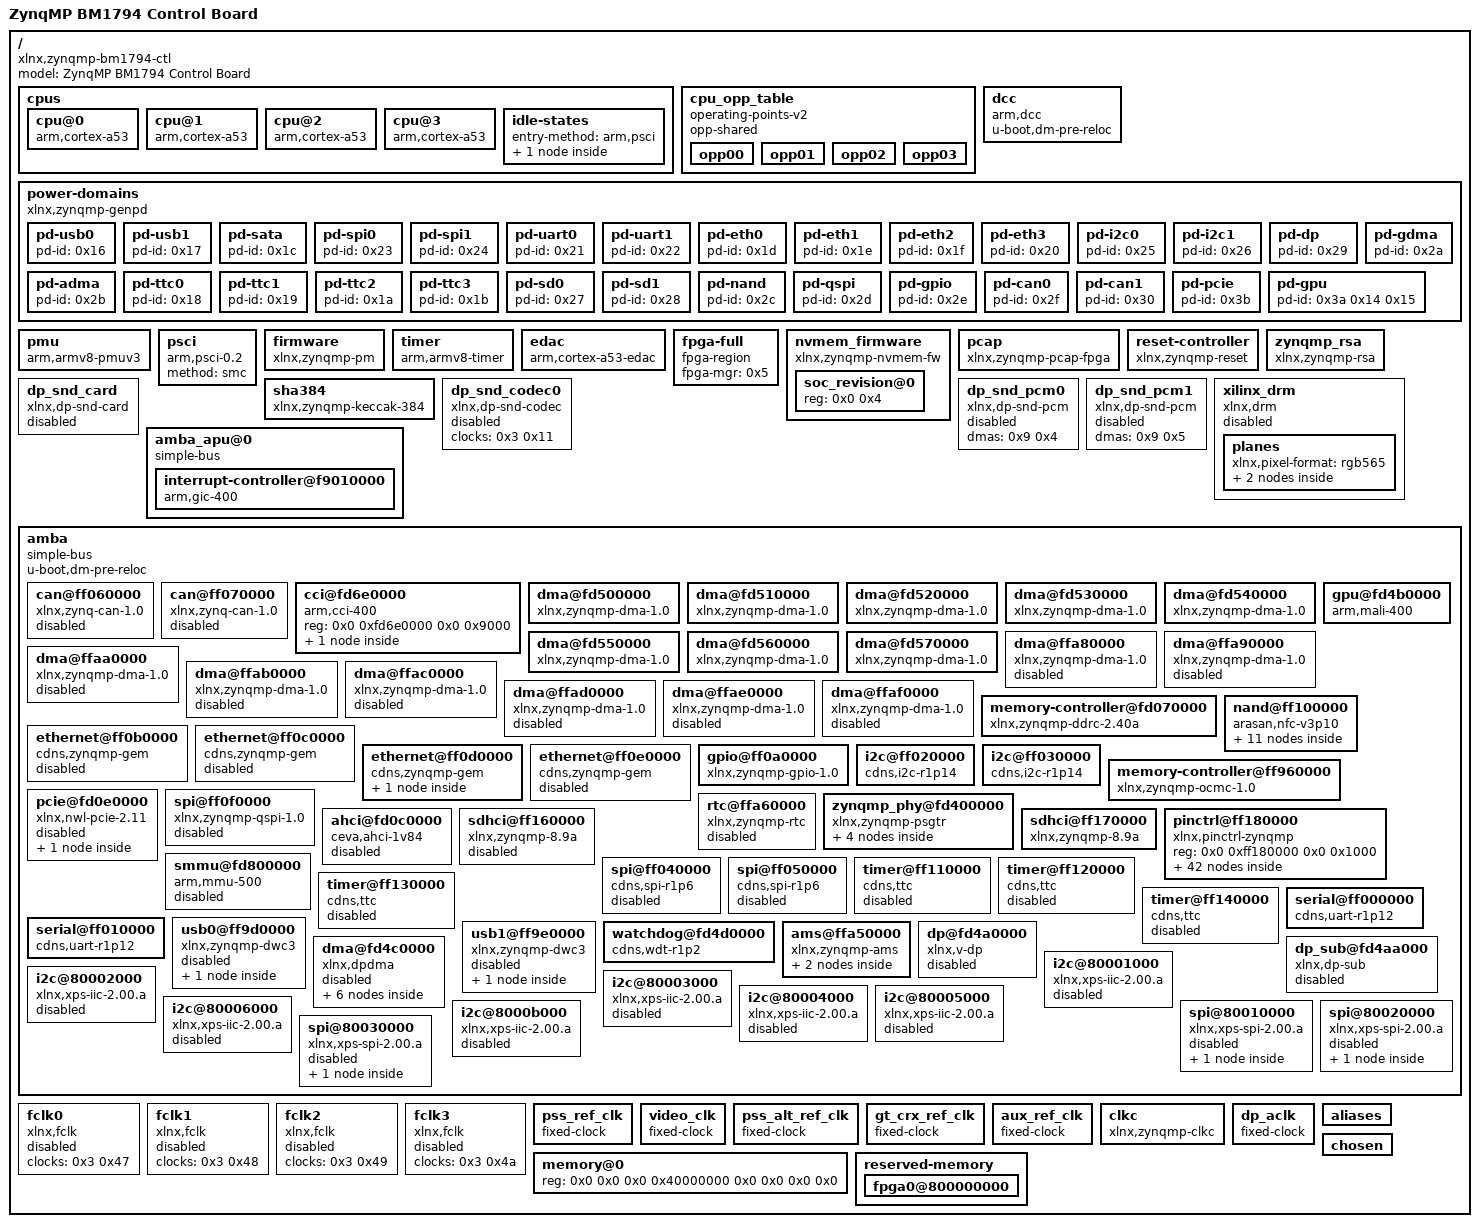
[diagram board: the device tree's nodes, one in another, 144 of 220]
/dts-v1/;

/memreserve/	0x000000003d1ba000 0x0000000000009000;
/memreserve/	0x000000003d1c6000 0x0000000000cfb1b4;
/ {
	compatible = "xlnx,zynqmp-bm1794-ctl", "xlnx,zynqmp";
	#address-cells = <0x2>;
	#size-cells = <0x2>;
	model = "ZynqMP BM1794 Control Board";

	cpus {
		#address-cells = <0x1>;
		#size-cells = <0x0>;

		cpu@0 {
			compatible = "arm,cortex-a53", "arm,armv8";
			device_type = "cpu";
			enable-method = "psci";
			operating-points-v2 = <0x1>;
			reg = <0x0>;
			cpu-idle-states = <0x2>;
			clocks = <0x3 0xa>;
		};

		cpu@1 {
			compatible = "arm,cortex-a53", "arm,armv8";
			device_type = "cpu";
			enable-method = "psci";
			reg = <0x1>;
			operating-points-v2 = <0x1>;
			cpu-idle-states = <0x2>;
		};

		cpu@2 {
			compatible = "arm,cortex-a53", "arm,armv8";
			device_type = "cpu";
			enable-method = "psci";
			reg = <0x2>;
			operating-points-v2 = <0x1>;
			cpu-idle-states = <0x2>;
		};

		cpu@3 {
			compatible = "arm,cortex-a53", "arm,armv8";
			device_type = "cpu";
			enable-method = "psci";
			reg = <0x3>;
			operating-points-v2 = <0x1>;
			cpu-idle-states = <0x2>;
		};

		idle-states {
			entry-method = "arm,psci";

			cpu-sleep-0 {
				compatible = "arm,idle-state";
				arm,psci-suspend-param = <0x40000000>;
				local-timer-stop;
				entry-latency-us = <0x12c>;
				exit-latency-us = <0x258>;
				min-residency-us = <0x2710>;
				linux,phandle = <0x2>;
				phandle = <0x2>;
			};
		};
	};

	cpu_opp_table {
		compatible = "operating-points-v2";
		opp-shared;
		linux,phandle = <0x1>;
		phandle = <0x1>;

		opp00 {
			opp-hz = <0x0 0x47868bf4>;
			opp-microvolt = <0xf4240>;
			clock-latency-ns = <0x7a120>;
		};

		opp01 {
			opp-hz = <0x0 0x23c345fa>;
			opp-microvolt = <0xf4240>;
			clock-latency-ns = <0x7a120>;
		};

		opp02 {
			opp-hz = <0x0 0x17d783fc>;
			opp-microvolt = <0xf4240>;
			clock-latency-ns = <0x7a120>;
		};

		opp03 {
			opp-hz = <0x0 0x11e1a2fd>;
			opp-microvolt = <0xf4240>;
			clock-latency-ns = <0x7a120>;
		};
	};

	dcc {
		compatible = "arm,dcc";
		status = "okay";
		u-boot,dm-pre-reloc;
	};

	power-domains {
		compatible = "xlnx,zynqmp-genpd";

		pd-usb0 {
			#power-domain-cells = <0x0>;
			pd-id = <0x16>;
			linux,phandle = <0x38>;
			phandle = <0x38>;
		};

		pd-usb1 {
			#power-domain-cells = <0x0>;
			pd-id = <0x17>;
			linux,phandle = <0x39>;
			phandle = <0x39>;
		};

		pd-sata {
			#power-domain-cells = <0x0>;
			pd-id = <0x1c>;
			linux,phandle = <0x28>;
			phandle = <0x28>;
		};

		pd-spi0 {
			#power-domain-cells = <0x0>;
			pd-id = <0x23>;
			linux,phandle = <0x2e>;
			phandle = <0x2e>;
		};

		pd-spi1 {
			#power-domain-cells = <0x0>;
			pd-id = <0x24>;
			linux,phandle = <0x2f>;
			phandle = <0x2f>;
		};

		pd-uart0 {
			#power-domain-cells = <0x0>;
			pd-id = <0x21>;
			linux,phandle = <0x34>;
			phandle = <0x34>;
		};

		pd-uart1 {
			#power-domain-cells = <0x0>;
			pd-id = <0x22>;
			linux,phandle = <0x36>;
			phandle = <0x36>;
		};

		pd-eth0 {
			#power-domain-cells = <0x0>;
			pd-id = <0x1d>;
			linux,phandle = <0x13>;
			phandle = <0x13>;
		};

		pd-eth1 {
			#power-domain-cells = <0x0>;
			pd-id = <0x1e>;
			linux,phandle = <0x14>;
			phandle = <0x14>;
		};

		pd-eth2 {
			#power-domain-cells = <0x0>;
			pd-id = <0x1f>;
			linux,phandle = <0x15>;
			phandle = <0x15>;
		};

		pd-eth3 {
			#power-domain-cells = <0x0>;
			pd-id = <0x20>;
			linux,phandle = <0x18>;
			phandle = <0x18>;
		};

		pd-i2c0 {
			#power-domain-cells = <0x0>;
			pd-id = <0x25>;
			linux,phandle = <0x1b>;
			phandle = <0x1b>;
		};

		pd-i2c1 {
			#power-domain-cells = <0x0>;
			pd-id = <0x26>;
			linux,phandle = <0x1f>;
			phandle = <0x1f>;
		};

		pd-dp {
			#power-domain-cells = <0x0>;
			pd-id = <0x29>;
			linux,phandle = <0x3a>;
			phandle = <0x3a>;
		};

		pd-gdma {
			#power-domain-cells = <0x0>;
			pd-id = <0x2a>;
			linux,phandle = <0xf>;
			phandle = <0xf>;
		};

		pd-adma {
			#power-domain-cells = <0x0>;
			pd-id = <0x2b>;
			linux,phandle = <0x11>;
			phandle = <0x11>;
		};

		pd-ttc0 {
			#power-domain-cells = <0x0>;
			pd-id = <0x18>;
			linux,phandle = <0x30>;
			phandle = <0x30>;
		};

		pd-ttc1 {
			#power-domain-cells = <0x0>;
			pd-id = <0x19>;
			linux,phandle = <0x31>;
			phandle = <0x31>;
		};

		pd-ttc2 {
			#power-domain-cells = <0x0>;
			pd-id = <0x1a>;
			linux,phandle = <0x32>;
			phandle = <0x32>;
		};

		pd-ttc3 {
			#power-domain-cells = <0x0>;
			pd-id = <0x1b>;
			linux,phandle = <0x33>;
			phandle = <0x33>;
		};

		pd-sd0 {
			#power-domain-cells = <0x0>;
			pd-id = <0x27>;
			linux,phandle = <0x2a>;
			phandle = <0x2a>;
		};

		pd-sd1 {
			#power-domain-cells = <0x0>;
			pd-id = <0x28>;
			linux,phandle = <0x2c>;
			phandle = <0x2c>;
		};

		pd-nand {
			#power-domain-cells = <0x0>;
			pd-id = <0x2c>;
			linux,phandle = <0x12>;
			phandle = <0x12>;
		};

		pd-qspi {
			#power-domain-cells = <0x0>;
			pd-id = <0x2d>;
			linux,phandle = <0x25>;
			phandle = <0x25>;
		};

		pd-gpio {
			#power-domain-cells = <0x0>;
			pd-id = <0x2e>;
			linux,phandle = <0x19>;
			phandle = <0x19>;
		};

		pd-can0 {
			#power-domain-cells = <0x0>;
			pd-id = <0x2f>;
			linux,phandle = <0xc>;
			phandle = <0xc>;
		};

		pd-can1 {
			#power-domain-cells = <0x0>;
			pd-id = <0x30>;
			linux,phandle = <0xd>;
			phandle = <0xd>;
		};

		pd-pcie {
			#power-domain-cells = <0x0>;
			pd-id = <0x3b>;
			linux,phandle = <0x24>;
			phandle = <0x24>;
		};

		pd-gpu {
			#power-domain-cells = <0x0>;
			pd-id = <0x3a 0x14 0x15>;
			linux,phandle = <0x10>;
			phandle = <0x10>;
		};
	};

	pmu {
		compatible = "arm,armv8-pmuv3";
		interrupt-parent = <0x4>;
		interrupts = <0x0 0x8f 0x4 0x0 0x90 0x4 0x0 0x91 0x4 0x0 0x92 0x4>;
	};

	psci {
		compatible = "arm,psci-0.2";
		method = "smc";
	};

	firmware {
		compatible = "xlnx,zynqmp-pm";
		method = "smc";
		interrupt-parent = <0x4>;
		interrupts = <0x0 0x23 0x4>;
	};

	timer {
		compatible = "arm,armv8-timer";
		interrupt-parent = <0x4>;
		interrupts = <0x1 0xd 0xf08 0x1 0xe 0xf08 0x1 0xb 0xf08 0x1 0xa 0xf08>;
	};

	edac {
		compatible = "arm,cortex-a53-edac";
	};

	fpga-full {
		compatible = "fpga-region";
		fpga-mgr = <0x5>;
		#address-cells = <0x2>;
		#size-cells = <0x2>;
	};

	nvmem_firmware {
		compatible = "xlnx,zynqmp-nvmem-fw";
		#address-cells = <0x1>;
		#size-cells = <0x1>;

		soc_revision@0 {
			reg = <0x0 0x4>;
			linux,phandle = <0x26>;
			phandle = <0x26>;
		};
	};

	pcap {
		compatible = "xlnx,zynqmp-pcap-fpga";
		linux,phandle = <0x5>;
		phandle = <0x5>;
	};

	reset-controller {
		compatible = "xlnx,zynqmp-reset";
		#reset-cells = <0x1>;
		linux,phandle = <0x27>;
		phandle = <0x27>;
	};

	zynqmp_rsa {
		compatible = "xlnx,zynqmp-rsa";
	};

	sha384 {
		compatible = "xlnx,zynqmp-keccak-384";
	};

	dp_snd_card {
		compatible = "xlnx,dp-snd-card";
		status = "disabled";
		xlnx,dp-snd-pcm = <0x6 0x7>;
		xlnx,dp-snd-codec = <0x8>;
	};

	dp_snd_codec0 {
		compatible = "xlnx,dp-snd-codec";
		status = "disabled";
		clock-names = "aud_clk";
		clocks = <0x3 0x11>;
		linux,phandle = <0x8>;
		phandle = <0x8>;
	};

	dp_snd_pcm0 {
		compatible = "xlnx,dp-snd-pcm";
		status = "disabled";
		dmas = <0x9 0x4>;
		dma-names = "tx";
		linux,phandle = <0x6>;
		phandle = <0x6>;
	};

	dp_snd_pcm1 {
		compatible = "xlnx,dp-snd-pcm";
		status = "disabled";
		dmas = <0x9 0x5>;
		dma-names = "tx";
		linux,phandle = <0x7>;
		phandle = <0x7>;
	};

	xilinx_drm {
		compatible = "xlnx,drm";
		status = "disabled";
		xlnx,encoder-slave = <0xa>;
		xlnx,connector-type = "DisplayPort";
		xlnx,dp-sub = <0xb>;
		clocks = <0x3 0x10>;

		planes {
			xlnx,pixel-format = "rgb565";

			plane0 {
				dmas = <0x9 0x3>;
				dma-names = "dma0";
			};

			plane1 {
				dmas = <0x9 0x0 0x9 0x1 0x9 0x2>;
				dma-names = "dma0", "dma1", "dma2";
			};
		};
	};

	amba_apu@0 {
		compatible = "simple-bus";
		#address-cells = <0x2>;
		#size-cells = <0x1>;
		ranges = <0x0 0x0 0x0 0x0 0xffffffff>;

		interrupt-controller@f9010000 {
			compatible = "arm,gic-400", "arm,cortex-a15-gic";
			#interrupt-cells = <0x3>;
			reg = <0x0 0xf9010000 0x10000 0x0 0xf9020000 0x20000 0x0 0xf9040000 0x20000 0x0 0xf9060000 0x20000>;
			interrupt-controller;
			interrupt-parent = <0x4>;
			interrupts = <0x1 0x9 0xf04>;
			linux,phandle = <0x4>;
			phandle = <0x4>;
		};
	};

	amba {
		compatible = "simple-bus";
		u-boot,dm-pre-reloc;
		#address-cells = <0x2>;
		#size-cells = <0x2>;
		ranges;

		can@ff060000 {
			compatible = "xlnx,zynq-can-1.0";
			status = "disabled";
			clock-names = "can_clk", "pclk";
			reg = <0x0 0xff060000 0x0 0x1000>;
			interrupts = <0x0 0x17 0x4>;
			interrupt-parent = <0x4>;
			tx-fifo-depth = <0x40>;
			rx-fifo-depth = <0x40>;
			power-domains = <0xc>;
			clocks = <0x3 0x3f 0x3 0x1f>;
		};

		can@ff070000 {
			compatible = "xlnx,zynq-can-1.0";
			status = "disabled";
			clock-names = "can_clk", "pclk";
			reg = <0x0 0xff070000 0x0 0x1000>;
			interrupts = <0x0 0x18 0x4>;
			interrupt-parent = <0x4>;
			tx-fifo-depth = <0x40>;
			rx-fifo-depth = <0x40>;
			power-domains = <0xd>;
			clocks = <0x3 0x40 0x3 0x1f>;
		};

		cci@fd6e0000 {
			compatible = "arm,cci-400";
			reg = <0x0 0xfd6e0000 0x0 0x9000>;
			ranges = <0x0 0x0 0xfd6e0000 0x10000>;
			#address-cells = <0x1>;
			#size-cells = <0x1>;

			pmu@9000 {
				compatible = "arm,cci-400-pmu,r1";
				reg = <0x9000 0x5000>;
				interrupt-parent = <0x4>;
				interrupts = <0x0 0x7b 0x4 0x0 0x7b 0x4 0x0 0x7b 0x4 0x0 0x7b 0x4 0x0 0x7b 0x4>;
			};
		};

		dma@fd500000 {
			status = "okay";
			compatible = "xlnx,zynqmp-dma-1.0";
			reg = <0x0 0xfd500000 0x0 0x1000>;
			interrupt-parent = <0x4>;
			interrupts = <0x0 0x7c 0x4>;
			clock-names = "clk_main", "clk_apb";
			xlnx,bus-width = <0x80>;
			#stream-id-cells = <0x1>;
			iommus = <0xe 0x14e8>;
			power-domains = <0xf>;
			clocks = <0x3 0x13 0x3 0x1f>;
		};

		dma@fd510000 {
			status = "okay";
			compatible = "xlnx,zynqmp-dma-1.0";
			reg = <0x0 0xfd510000 0x0 0x1000>;
			interrupt-parent = <0x4>;
			interrupts = <0x0 0x7d 0x4>;
			clock-names = "clk_main", "clk_apb";
			xlnx,bus-width = <0x80>;
			#stream-id-cells = <0x1>;
			iommus = <0xe 0x14e9>;
			power-domains = <0xf>;
			clocks = <0x3 0x13 0x3 0x1f>;
		};

		dma@fd520000 {
			status = "okay";
			compatible = "xlnx,zynqmp-dma-1.0";
			reg = <0x0 0xfd520000 0x0 0x1000>;
			interrupt-parent = <0x4>;
			interrupts = <0x0 0x7e 0x4>;
			clock-names = "clk_main", "clk_apb";
			xlnx,bus-width = <0x80>;
			#stream-id-cells = <0x1>;
			iommus = <0xe 0x14ea>;
			power-domains = <0xf>;
			clocks = <0x3 0x13 0x3 0x1f>;
		};

		dma@fd530000 {
			status = "okay";
			compatible = "xlnx,zynqmp-dma-1.0";
			reg = <0x0 0xfd530000 0x0 0x1000>;
			interrupt-parent = <0x4>;
			interrupts = <0x0 0x7f 0x4>;
			clock-names = "clk_main", "clk_apb";
			xlnx,bus-width = <0x80>;
			#stream-id-cells = <0x1>;
			iommus = <0xe 0x14eb>;
			power-domains = <0xf>;
			clocks = <0x3 0x13 0x3 0x1f>;
		};

		dma@fd540000 {
			status = "okay";
			compatible = "xlnx,zynqmp-dma-1.0";
			reg = <0x0 0xfd540000 0x0 0x1000>;
			interrupt-parent = <0x4>;
			interrupts = <0x0 0x80 0x4>;
			clock-names = "clk_main", "clk_apb";
			xlnx,bus-width = <0x80>;
			#stream-id-cells = <0x1>;
			iommus = <0xe 0x14ec>;
			power-domains = <0xf>;
			clocks = <0x3 0x13 0x3 0x1f>;
		};

		dma@fd550000 {
			status = "okay";
			compatible = "xlnx,zynqmp-dma-1.0";
			reg = <0x0 0xfd550000 0x0 0x1000>;
			interrupt-parent = <0x4>;
			interrupts = <0x0 0x81 0x4>;
			clock-names = "clk_main", "clk_apb";
			xlnx,bus-width = <0x80>;
			#stream-id-cells = <0x1>;
			iommus = <0xe 0x14ed>;
			power-domains = <0xf>;
			clocks = <0x3 0x13 0x3 0x1f>;
		};

		dma@fd560000 {
			status = "okay";
			compatible = "xlnx,zynqmp-dma-1.0";
			reg = <0x0 0xfd560000 0x0 0x1000>;
			interrupt-parent = <0x4>;
			interrupts = <0x0 0x82 0x4>;
			clock-names = "clk_main", "clk_apb";
			xlnx,bus-width = <0x80>;
			#stream-id-cells = <0x1>;
			iommus = <0xe 0x14ee>;
			power-domains = <0xf>;
			clocks = <0x3 0x13 0x3 0x1f>;
		};

		dma@fd570000 {
			status = "okay";
			compatible = "xlnx,zynqmp-dma-1.0";
			reg = <0x0 0xfd570000 0x0 0x1000>;
			interrupt-parent = <0x4>;
			interrupts = <0x0 0x83 0x4>;
			clock-names = "clk_main", "clk_apb";
			xlnx,bus-width = <0x80>;
			#stream-id-cells = <0x1>;
			iommus = <0xe 0x14ef>;
			power-domains = <0xf>;
			clocks = <0x3 0x13 0x3 0x1f>;
		};

		gpu@fd4b0000 {
			status = "okay";
			compatible = "arm,mali-400", "arm,mali-utgard";
			reg = <0x0 0xfd4b0000 0x0 0x10000>;
			interrupt-parent = <0x4>;
			interrupts = <0x0 0x84 0x4 0x0 0x84 0x4 0x0 0x84 0x4 0x0 0x84 0x4 0x0 0x84 0x4 0x0 0x84 0x4>;
			interrupt-names = "IRQGP", "IRQGPMMU", "IRQPP0", "IRQPPMMU0", "IRQPP1", "IRQPPMMU1";
			clock-names = "gpu", "gpu_pp0", "gpu_pp1";
			power-domains = <0x10>;
			clocks = <0x3 0x18 0x3 0x19 0x3 0x1a>;
		};

		dma@ffa80000 {
			status = "disabled";
			compatible = "xlnx,zynqmp-dma-1.0";
			clock-names = "clk_main", "clk_apb";
			reg = <0x0 0xffa80000 0x0 0x1000>;
			interrupt-parent = <0x4>;
			interrupts = <0x0 0x4d 0x4>;
			xlnx,bus-width = <0x40>;
			#stream-id-cells = <0x1>;
			power-domains = <0x11>;
			clocks = <0x3 0x44 0x3 0x1f>;
		};

		dma@ffa90000 {
			status = "disabled";
			compatible = "xlnx,zynqmp-dma-1.0";
			clock-names = "clk_main", "clk_apb";
			reg = <0x0 0xffa90000 0x0 0x1000>;
			interrupt-parent = <0x4>;
			interrupts = <0x0 0x4e 0x4>;
			xlnx,bus-width = <0x40>;
			#stream-id-cells = <0x1>;
			power-domains = <0x11>;
			clocks = <0x3 0x44 0x3 0x1f>;
		};

		dma@ffaa0000 {
			status = "disabled";
			compatible = "xlnx,zynqmp-dma-1.0";
			clock-names = "clk_main", "clk_apb";
			reg = <0x0 0xffaa0000 0x0 0x1000>;
			interrupt-parent = <0x4>;
			interrupts = <0x0 0x4f 0x4>;
			xlnx,bus-width = <0x40>;
			#stream-id-cells = <0x1>;
			power-domains = <0x11>;
			clocks = <0x3 0x44 0x3 0x1f>;
		};

		dma@ffab0000 {
			status = "disabled";
			compatible = "xlnx,zynqmp-dma-1.0";
			clock-names = "clk_main", "clk_apb";
			reg = <0x0 0xffab0000 0x0 0x1000>;
			interrupt-parent = <0x4>;
			interrupts = <0x0 0x50 0x4>;
			xlnx,bus-width = <0x40>;
			#stream-id-cells = <0x1>;
			power-domains = <0x11>;
			clocks = <0x3 0x44 0x3 0x1f>;
		};

		dma@ffac0000 {
			status = "disabled";
			compatible = "xlnx,zynqmp-dma-1.0";
			clock-names = "clk_main", "clk_apb";
			reg = <0x0 0xffac0000 0x0 0x1000>;
			interrupt-parent = <0x4>;
			interrupts = <0x0 0x51 0x4>;
			xlnx,bus-width = <0x40>;
			#stream-id-cells = <0x1>;
			power-domains = <0x11>;
			clocks = <0x3 0x44 0x3 0x1f>;
		};

		dma@ffad0000 {
			status = "disabled";
			compatible = "xlnx,zynqmp-dma-1.0";
			clock-names = "clk_main", "clk_apb";
			reg = <0x0 0xffad0000 0x0 0x1000>;
			interrupt-parent = <0x4>;
			interrupts = <0x0 0x52 0x4>;
			xlnx,bus-width = <0x40>;
			#stream-id-cells = <0x1>;
			power-domains = <0x11>;
			clocks = <0x3 0x44 0x3 0x1f>;
		};

		dma@ffae0000 {
			status = "disabled";
			compatible = "xlnx,zynqmp-dma-1.0";
			clock-names = "clk_main", "clk_apb";
			reg = <0x0 0xffae0000 0x0 0x1000>;
			interrupt-parent = <0x4>;
			interrupts = <0x0 0x53 0x4>;
			xlnx,bus-width = <0x40>;
			#stream-id-cells = <0x1>;
			power-domains = <0x11>;
			clocks = <0x3 0x44 0x3 0x1f>;
		};

		dma@ffaf0000 {
			status = "disabled";
			compatible = "xlnx,zynqmp-dma-1.0";
			clock-names = "clk_main", "clk_apb";
			reg = <0x0 0xffaf0000 0x0 0x1000>;
			interrupt-parent = <0x4>;
			interrupts = <0x0 0x54 0x4>;
			xlnx,bus-width = <0x40>;
			#stream-id-cells = <0x1>;
			power-domains = <0x11>;
			clocks = <0x3 0x44 0x3 0x1f>;
		};

		memory-controller@fd070000 {
			compatible = "xlnx,zynqmp-ddrc-2.40a";
			reg = <0x0 0xfd070000 0x0 0x30000>;
			interrupt-parent = <0x4>;
			interrupts = <0x0 0x70 0x4>;
		};

		nand@ff100000 {
			compatible = "arasan,nfc-v3p10";
			status = "okay";
			reg = <0x0 0xff100000 0x0 0x1000>;
			clock-names = "clk_sys", "clk_flash";
			interrupt-parent = <0x4>;
			interrupts = <0x0 0xe 0x4>;
			#address-cells = <0x1>;
			#size-cells = <0x0>;
			#stream-id-cells = <0x1>;
			iommus = <0xe 0x872>;
			power-domains = <0x12>;
			clocks = <0x3 0x3c 0x3 0x1f>;
			arasan,has-mdma;

			nand@0 {
				reg = <0x0>;
				#address-cells = <0x2>;
				#size-cells = <0x1>;

				partition@0 {
					label = "nand-fsbl-uboot";
					reg = <0x0 0x0 0x800000>;
				};

				partition@1 {
					label = "nand-fsbl-uboot";
					reg = <0x0 0x800000 0x800000>;
				};

				partition@2 {
					label = "nand-fsbl-uboot";
					reg = <0x0 0x1000000 0x800000>;
				};

				partition@3 {
					label = "nand-fsbl-reserve";
					reg = <0x0 0x1800000 0x200000>;
				};

				partition@4 {
					label = "nand-linux-uimage";
					reg = <0x0 0x1a00000 0x1000000>;
				};

				partition@5 {
					label = "device-tree";
					reg = <0x0 0x2a00000 0x100000>;
				};

				partition@6 {
					label = "nand-uramdisk-image";
					reg = <0x0 0x2b00000 0x2000000>;
				};

				partition@7 {
					label = "nand-config";
					reg = <0x0 0x4b00000 0x800000>;
				};

				partition@8 {
					label = "nand-reserve";
					reg = <0x0 0x5300000 0xd00000>;
				};

				partition@9 {
					label = "nand-uramdisk-bak";
					reg = <0x0 0x6000000 0x2000000>;
				};
			};
		};

		ethernet@ff0b0000 {
			compatible = "cdns,zynqmp-gem";
			status = "disabled";
			interrupt-parent = <0x4>;
			interrupts = <0x0 0x39 0x4 0x0 0x39 0x4>;
			reg = <0x0 0xff0b0000 0x0 0x1000>;
			clock-names = "pclk", "tx_clk", "hclk";
			#address-cells = <0x1>;
			#size-cells = <0x0>;
			#stream-id-cells = <0x1>;
			iommus = <0xe 0x874>;
			power-domains = <0x13>;
			clocks = <0x3 0x2d 0x3 0x2d 0x3 0x31>;
		};

		ethernet@ff0c0000 {
			compatible = "cdns,zynqmp-gem";
			status = "disabled";
			interrupt-parent = <0x4>;
			interrupts = <0x0 0x3b 0x4 0x0 0x3b 0x4>;
			reg = <0x0 0xff0c0000 0x0 0x1000>;
			clock-names = "pclk", "tx_clk", "hclk";
			#address-cells = <0x1>;
			#size-cells = <0x0>;
			#stream-id-cells = <0x1>;
			iommus = <0xe 0x875>;
			power-domains = <0x14>;
			clocks = <0x3 0x2e 0x3 0x2e 0x3 0x32>;
		};

		ethernet@ff0d0000 {
			compatible = "cdns,zynqmp-gem";
			status = "okay";
			interrupt-parent = <0x4>;
			interrupts = <0x0 0x3d 0x4 0x0 0x3d 0x4>;
			reg = <0x0 0xff0d0000 0x0 0x1000>;
			clock-names = "pclk", "tx_clk", "hclk";
			#address-cells = <0x1>;
			#size-cells = <0x0>;
			#stream-id-cells = <0x1>;
			iommus = <0xe 0x876>;
			power-domains = <0x15>;
			clocks = <0x3 0x2f 0x3 0x2f 0x3 0x33>;
			phy-handle = <0x16>;
			phy-mode = "rgmii-id";
			pinctrl-names = "default";
			pinctrl-0 = <0x17>;

			phy@0 {
				reg = <0x0>;
				ti,rx-internal-delay = <0x8>;
				ti,tx-internal-delay = <0xa>;
				ti,fifo-depth = <0x1>;
				ti,rxctrl-strap-worka;
				linux,phandle = <0x16>;
				phandle = <0x16>;
			};
		};

		ethernet@ff0e0000 {
			compatible = "cdns,zynqmp-gem";
			status = "disabled";
			interrupt-parent = <0x4>;
			interrupts = <0x0 0x3f 0x4 0x0 0x3f 0x4>;
			reg = <0x0 0xff0e0000 0x0 0x1000>;
			clock-names = "pclk", "hclk", "tx_clk", "rx_clk";
			#address-cells = <0x1>;
			#size-cells = <0x0>;
			#stream-id-cells = <0x1>;
			iommus = <0xe 0x877>;
			power-domains = <0x18>;
			clocks = <0x3 0x1f 0x3 0x34 0x3 0x30 0x3 0x34>;
		};

		gpio@ff0a0000 {
			compatible = "xlnx,zynqmp-gpio-1.0";
			status = "okay";
			#gpio-cells = <0x2>;
			interrupt-parent = <0x4>;
			interrupts = <0x0 0x10 0x4>;
			interrupt-controller;
			#interrupt-cells = <0x2>;
			reg = <0x0 0xff0a0000 0x0 0x1000>;
			gpio-controller;
			power-domains = <0x19>;
			clocks = <0x3 0x1f>;
			pinctrl-names = "default";
			pinctrl-0 = <0x1a>;
			linux,phandle = <0x1e>;
			phandle = <0x1e>;
		};

		i2c@ff020000 {
			compatible = "cdns,i2c-r1p14", "cdns,i2c-r1p10";
			status = "okay";
			interrupt-parent = <0x4>;
			interrupts = <0x0 0x11 0x4>;
			reg = <0x0 0xff020000 0x0 0x1000>;
			#address-cells = <0x1>;
			#size-cells = <0x0>;
			power-domains = <0x1b>;
			clocks = <0x3 0x3d>;
			clock-frequency = <0x61a80>;
			pinctrl-names = "default", "gpio";
			pinctrl-0 = <0x1c>;
			pinctrl-1 = <0x1d>;
			scl-gpios = <0x1e 0x22 0x0>;
			sda-gpios = <0x1e 0x23 0x0>;
		};

		i2c@ff030000 {
			compatible = "cdns,i2c-r1p14", "cdns,i2c-r1p10";
			status = "okay";
			interrupt-parent = <0x4>;
			interrupts = <0x0 0x12 0x4>;
			reg = <0x0 0xff030000 0x0 0x1000>;
			#address-cells = <0x1>;
			#size-cells = <0x0>;
			power-domains = <0x1f>;
			clocks = <0x3 0x3e>;
			clock-frequency = <0x61a80>;
			pinctrl-names = "default", "gpio";
			pinctrl-0 = <0x20>;
			pinctrl-1 = <0x21>;
			scl-gpios = <0x1e 0x24 0x0>;
			sda-gpios = <0x1e 0x25 0x0>;
		};

		memory-controller@ff960000 {
			compatible = "xlnx,zynqmp-ocmc-1.0";
			reg = <0x0 0xff960000 0x0 0x1000>;
			interrupt-parent = <0x4>;
			interrupts = <0x0 0xa 0x4>;
		};

		pcie@fd0e0000 {
			compatible = "xlnx,nwl-pcie-2.11";
			status = "disabled";
			#address-cells = <0x3>;
			#size-cells = <0x2>;
			#interrupt-cells = <0x1>;
			msi-controller;
			device_type = "pci";
			interrupt-parent = <0x4>;
			interrupts = <0x0 0x76 0x4 0x0 0x75 0x4 0x0 0x74 0x4 0x0 0x73 0x4 0x0 0x72 0x4>;
			interrupt-names = "misc", "dummy", "intx", "msi1", "msi0";
			msi-parent = <0x22>;
			reg = <0x0 0xfd0e0000 0x0 0x1000 0x0 0xfd480000 0x0 0x1000 0x80 0x0 0x0 0x1000000>;
			reg-names = "breg", "pcireg", "cfg";
			ranges = <0x2000000 0x0 0xe0000000 0x0 0xe0000000 0x0 0x10000000 0x43000000 0x6 0x0 0x6 0x0 0x2 0x0>;
			bus-range = <0x0 0xff>;
			interrupt-map-mask = <0x0 0x0 0x0 0x7>;
			interrupt-map = <0x0 0x0 0x0 0x1 0x23 0x1 0x0 0x0 0x0 0x2 0x23 0x2 0x0 0x0 0x0 0x3 0x23 0x3 0x0 0x0 0x0 0x4 0x23 0x4>;
			power-domains = <0x24>;
			clocks = <0x3 0x17>;
			linux,phandle = <0x22>;
			phandle = <0x22>;

			legacy-interrupt-controller {
				interrupt-controller;
				#address-cells = <0x0>;
				#interrupt-cells = <0x1>;
				linux,phandle = <0x23>;
				phandle = <0x23>;
			};
		};

		spi@ff0f0000 {
			u-boot,dm-pre-reloc;
			compatible = "xlnx,zynqmp-qspi-1.0";
			status = "disabled";
			clock-names = "ref_clk", "pclk";
			interrupts = <0x0 0xf 0x4>;
			interrupt-parent = <0x4>;
			num-cs = <0x1>;
			reg = <0x0 0xff0f0000 0x0 0x1000 0x0 0xc0000000 0x0 0x8000000>;
			#address-cells = <0x1>;
			#size-cells = <0x0>;
			#stream-id-cells = <0x1>;
			iommus = <0xe 0x873>;
			power-domains = <0x25>;
			clocks = <0x3 0x35 0x3 0x1f>;
		};

		rtc@ffa60000 {
			compatible = "xlnx,zynqmp-rtc";
			status = "disabled";
			reg = <0x0 0xffa60000 0x0 0x100>;
			interrupt-parent = <0x4>;
			interrupts = <0x0 0x1a 0x4 0x0 0x1b 0x4>;
			interrupt-names = "alarm", "sec";
			calibration = <0x8000>;
		};

		zynqmp_phy@fd400000 {
			compatible = "xlnx,zynqmp-psgtr";
			status = "okay";
			reg = <0x0 0xfd400000 0x0 0x40000 0x0 0xfd3d0000 0x0 0x1000 0x0 0xff5e0000 0x0 0x1000>;
			reg-names = "serdes", "siou", "lpd";
			nvmem-cells = <0x26>;
			nvmem-cell-names = "soc_revision";
			resets = <0x27 0x10 0x27 0x3b 0x27 0x3c 0x27 0x3d 0x27 0x3e 0x27 0x3f 0x27 0x40 0x27 0x3 0x27 0x1d 0x27 0x1e 0x27 0x1f 0x27 0x20>;
			reset-names = "sata_rst", "usb0_crst", "usb1_crst", "usb0_hibrst", "usb1_hibrst", "usb0_apbrst", "usb1_apbrst", "dp_rst", "gem0_rst", "gem1_rst", "gem2_rst", "gem3_rst";

			lane0 {
				#phy-cells = <0x4>;
				linux,phandle = <0x29>;
				phandle = <0x29>;
			};

			lane1 {
				#phy-cells = <0x4>;
			};

			lane2 {
				#phy-cells = <0x4>;
			};

			lane3 {
				#phy-cells = <0x4>;
			};
		};

		ahci@fd0c0000 {
			compatible = "ceva,ahci-1v84";
			status = "disabled";
			reg = <0x0 0xfd0c0000 0x0 0x2000>;
			interrupt-parent = <0x4>;
			interrupts = <0x0 0x85 0x4>;
			power-domains = <0x28>;
			#stream-id-cells = <0x4>;
			iommus = <0xe 0x4c0 0xe 0x4c1 0xe 0x4c2 0xe 0x4c3>;
			clocks = <0x3 0x16>;
			ceva,p0-cominit-params = <0x18401828>;
			ceva,p0-comwake-params = <0x614080e>;
			ceva,p0-burst-params = <0x13084a06>;
			ceva,p0-retry-params = <0x96a43ffc>;
			ceva,p1-cominit-params = <0x18401828>;
			ceva,p1-comwake-params = <0x614080e>;
			ceva,p1-burst-params = <0x13084a06>;
			ceva,p1-retry-params = <0x96a43ffc>;
			phy-names = "sata-phy";
			phys = <0x29 0x1 0x0 0x0 0x7735940>;
		};

		sdhci@ff160000 {
			u-boot,dm-pre-reloc;
			compatible = "xlnx,zynqmp-8.9a", "arasan,sdhci-8.9a";
			status = "disabled";
			interrupt-parent = <0x4>;
			interrupts = <0x0 0x30 0x4>;
			reg = <0x0 0xff160000 0x0 0x1000>;
			clock-names = "clk_xin", "clk_ahb";
			xlnx,device_id = <0x0>;
			#stream-id-cells = <0x1>;
			iommus = <0xe 0x870>;
			power-domains = <0x2a>;
			nvmem-cells = <0x26>;
			nvmem-cell-names = "soc_revision";
			clocks = <0x3 0x36 0x3 0x1f>;
			pinctrl-names = "default";
			pinctrl-0 = <0x2b>;
			no-1-8-v;
			xlnx,mio_bank = <0x0>;
		};

		sdhci@ff170000 {
			u-boot,dm-pre-reloc;
			compatible = "xlnx,zynqmp-8.9a", "arasan,sdhci-8.9a";
			status = "okay";
			interrupt-parent = <0x4>;
			interrupts = <0x0 0x31 0x4>;
			reg = <0x0 0xff170000 0x0 0x1000>;
			clock-names = "clk_xin", "clk_ahb";
			xlnx,device_id = <0x1>;
			#stream-id-cells = <0x1>;
			iommus = <0xe 0x871>;
			power-domains = <0x2c>;
			nvmem-cells = <0x26>;
			nvmem-cell-names = "soc_revision";
			clocks = <0x3 0x37 0x3 0x1f>;
			pinctrl-names = "default";
			pinctrl-0 = <0x2d>;
			no-1-8-v;
			xlnx,mio_bank = <0x1>;
		};

		pinctrl@ff180000 {
			compatible = "xlnx,pinctrl-zynqmp";
			status = "okay";
			reg = <0x0 0xff180000 0x0 0x1000>;

			i2c0-default {
				linux,phandle = <0x1c>;
				phandle = <0x1c>;

				mux {
					groups = "i2c0_8_grp";
					function = "i2c1";
				};

				conf {
					groups = "i2c0_8_grp";
					bias-pull-up;
					slew-rate = <0x1>;
					io-standard = <0x1>;
				};
			};

			i2c0-gpio {
				linux,phandle = <0x1d>;
				phandle = <0x1d>;

				mux {
					groups = "gpio0_33_grp", "gpio0_34_grp";
					function = "gpio1";
				};

				conf {
					groups = "gpio0_33_grp", "gpio0_34_grp";
					slew-rate = <0x1>;
					io-standard = <0x1>;
				};
			};

			i2c1-default {
				linux,phandle = <0x20>;
				phandle = <0x20>;

				mux {
					groups = "i2c1_9_grp";
					function = "i2c1";
				};

				conf {
					groups = "i2c1_9_grp";
					bias-pull-up;
					slew-rate = <0x1>;
					io-standard = <0x1>;
				};
			};

			i2c1-gpio {
				linux,phandle = <0x21>;
				phandle = <0x21>;

				mux {
					groups = "gpio0_35_grp", "gpio0_36_grp";
					function = "gpio1";
				};

				conf {
					groups = "gpio0_35_grp", "gpio0_36_grp";
					slew-rate = <0x1>;
					io-standard = <0x1>;
				};
			};

			uart0-default {
				linux,phandle = <0x35>;
				phandle = <0x35>;

				mux {
					groups = "uart0_7_grp";
					function = "uart0";
				};

				conf {
					groups = "uart0_7_grp";
					slew-rate = <0x1>;
					io-standard = <0x1>;
				};

				conf-rx {
					pins = "MIO30";
					bias-high-impedance;
				};

				conf-tx {
					pins = "MIO31";
					bias-disable;
				};
			};

			uart1-default {
				linux,phandle = <0x37>;
				phandle = <0x37>;

				mux {
					groups = "uart1_8_grp";
					function = "uart1";
				};

				conf {
					groups = "uart1_8_grp";
					slew-rate = <0x1>;
					io-standard = <0x1>;
				};

				conf-rx {
					pins = "MIO33";
					bias-high-impedance;
				};

				conf-tx {
					pins = "MIO32";
					bias-disable;
				};
			};

			gem2-default {
				linux,phandle = <0x17>;
				phandle = <0x17>;

				mux {
					function = "ethernet2";
					groups = "ethernet2_0_grp";
				};

				conf {
					groups = "ethernet2_0_grp";
					slew-rate = <0x1>;
					io-standard = <0x0>;
				};

				conf-rx {
					pins = "MIO52", "MIO53", "MIO54", "MIO55", "MIO56", "MIO57";
					bias-high-impedance;
					low-power-disable;
				};

				conf-tx {
					pins = "MIO56", "MIO57", "MIO58", "MIO59", "MIO50", "MIO51";
					bias-disable;
					low-power-enable;
				};

				mux-mdio {
					function = "mdio2";
					groups = "mdio2_0_grp";
				};

				conf-mdio {
					groups = "mdio2_0_grp";
					slew-rate = <0x1>;
					io-standard = <0x0>;
					bias-disable;
				};
			};

			sdhci0-default {
				linux,phandle = <0x2b>;
				phandle = <0x2b>;

				mux {
					groups = "sdio0_0_grp";
					function = "sdio0";
				};

				conf {
					groups = "sdio0_0_grp";
					slew-rate = <0x1>;
					io-standard = <0x1>;
					bias-disable;
				};
			};

			sdhci1-default {
				linux,phandle = <0x2d>;
				phandle = <0x2d>;

				mux {
					groups = "sdio1_4bit_0_1_grp";
					function = "sdio1";
				};

				conf {
					groups = "sdio1_4bit_0_1_grp";
					slew-rate = <0x1>;
					io-standard = <0x0>;
					bias-disable;
				};

				mux-cd {
					groups = "sdio1_0_cd_grp";
					function = "sdio1_cd";
				};

				conf-cd {
					groups = "sdio1_0_cd_grp";
					bias-high-impedance;
					bias-pull-up;
					slew-rate = <0x1>;
					io-standard = <0x0>;
				};

				mux-wp {
					groups = "sdio1_0_wp_grp";
					function = "sdio1_wp";
				};

				conf-wp {
					groups = "sdio1_0_wp_grp";
					bias-high-impedance;
					bias-pull-up;
					slew-rate = <0x1>;
					io-standard = <0x0>;
				};
			};

			gpio-default {
				linux,phandle = <0x1a>;
				phandle = <0x1a>;

				mux-sw {
					function = "gpio0";
					groups = "gpio0_26_grp", "gpio0_27_grp", "gpio0_28_grp", "gpio0_29_grp", "gpio0_38_grp", "gpio0_39_grp", "gpio0_40_grp", "gpio0_41_grp", "gpio0_42_grp", "gpio0_64_grp", "gpio0_65_grp", "gpio0_66_grp", "gpio0_67_grp", "gpio0_68_grp", "gpio0_69_grp", "gpio0_70_grp", "gpio0_71_grp", "gpio0_72_grp", "gpio0_73_grp", "gpio0_74_grp", "gpio0_75_grp";
				};

				conf-sw {
					groups = "gpio0_26_grp", "gpio0_27_grp", "gpio0_28_grp", "gpio0_29_grp", "gpio0_38_grp", "gpio0_39_grp", "gpio0_40_grp", "gpio0_41_grp", "gpio0_42_grp", "gpio0_64_grp", "gpio0_65_grp", "gpio0_66_grp", "gpio0_67_grp", "gpio0_68_grp", "gpio0_69_grp", "gpio0_70_grp", "gpio0_71_grp", "gpio0_72_grp", "gpio0_73_grp", "gpio0_74_grp", "gpio0_75_grp";
					slew-rate = <0x1>;
					io-standard = <0x1>;
				};
			};
		};

		smmu@fd800000 {
			compatible = "arm,mmu-500";
			reg = <0x0 0xfd800000 0x0 0x20000>;
			#iommu-cells = <0x1>;
			status = "disabled";
			#global-interrupts = <0x1>;
			interrupt-parent = <0x4>;
			interrupts = <0x0 0x9b 0x4 0x0 0x9b 0x4 0x0 0x9b 0x4 0x0 0x9b 0x4 0x0 0x9b 0x4 0x0 0x9b 0x4 0x0 0x9b 0x4 0x0 0x9b 0x4 0x0 0x9b 0x4 0x0 0x9b 0x4 0x0 0x9b 0x4 0x0 0x9b 0x4 0x0 0x9b 0x4 0x0 0x9b 0x4 0x0 0x9b 0x4 0x0 0x9b 0x4 0x0 0x9b 0x4>;
			linux,phandle = <0xe>;
			phandle = <0xe>;
		};

		spi@ff040000 {
			compatible = "cdns,spi-r1p6";
			status = "disabled";
			interrupt-parent = <0x4>;
			interrupts = <0x0 0x13 0x4>;
			reg = <0x0 0xff040000 0x0 0x1000>;
			clock-names = "ref_clk", "pclk";
			#address-cells = <0x1>;
			#size-cells = <0x0>;
			power-domains = <0x2e>;
			clocks = <0x3 0x3a 0x3 0x1f>;
		};

		spi@ff050000 {
			compatible = "cdns,spi-r1p6";
			status = "disabled";
			interrupt-parent = <0x4>;
			interrupts = <0x0 0x14 0x4>;
			reg = <0x0 0xff050000 0x0 0x1000>;
			clock-names = "ref_clk", "pclk";
			#address-cells = <0x1>;
			#size-cells = <0x0>;
			power-domains = <0x2f>;
			clocks = <0x3 0x3b 0x3 0x1f>;
		};

		timer@ff110000 {
			compatible = "cdns,ttc";
			status = "disabled";
			interrupt-parent = <0x4>;
			interrupts = <0x0 0x24 0x4 0x0 0x25 0x4 0x0 0x26 0x4>;
			reg = <0x0 0xff110000 0x0 0x1000>;
			timer-width = <0x20>;
			power-domains = <0x30>;
		};

		timer@ff120000 {
			compatible = "cdns,ttc";
			status = "disabled";
			interrupt-parent = <0x4>;
			interrupts = <0x0 0x27 0x4 0x0 0x28 0x4 0x0 0x29 0x4>;
			reg = <0x0 0xff120000 0x0 0x1000>;
			timer-width = <0x20>;
			power-domains = <0x31>;
		};

		timer@ff130000 {
			compatible = "cdns,ttc";
			status = "disabled";
			interrupt-parent = <0x4>;
			interrupts = <0x0 0x2a 0x4 0x0 0x2b 0x4 0x0 0x2c 0x4>;
			reg = <0x0 0xff130000 0x0 0x1000>;
			timer-width = <0x20>;
			power-domains = <0x32>;
		};

		timer@ff140000 {
			compatible = "cdns,ttc";
			status = "disabled";
			interrupt-parent = <0x4>;
			interrupts = <0x0 0x2d 0x4 0x0 0x2e 0x4 0x0 0x2f 0x4>;
			reg = <0x0 0xff140000 0x0 0x1000>;
			timer-width = <0x20>;
			power-domains = <0x33>;
		};

		serial@ff000000 {
			u-boot,dm-pre-reloc;
			compatible = "cdns,uart-r1p12", "xlnx,xuartps";
			status = "okay";
			interrupt-parent = <0x4>;
			interrupts = <0x0 0x15 0x4>;
			reg = <0x0 0xff000000 0x0 0x1000>;
			clock-names = "uart_clk", "pclk";
			power-domains = <0x34>;
			clocks = <0x3 0x38 0x3 0x1f>;
			pinctrl-names = "default";
			pinctrl-0 = <0x35>;
		};

		serial@ff010000 {
			u-boot,dm-pre-reloc;
			compatible = "cdns,uart-r1p12", "xlnx,xuartps";
			status = "okay";
			interrupt-parent = <0x4>;
			interrupts = <0x0 0x16 0x4>;
			reg = <0x0 0xff010000 0x0 0x1000>;
			clock-names = "uart_clk", "pclk";
			power-domains = <0x36>;
			clocks = <0x3 0x39 0x3 0x1f>;
			pinctrl-names = "default";
			pinctrl-0 = <0x37>;
		};

		usb0@ff9d0000 {
			#address-cells = <0x2>;
			#size-cells = <0x2>;
			status = "disabled";
			compatible = "xlnx,zynqmp-dwc3";
			reg = <0x0 0xff9d0000 0x0 0x100>;
			clock-names = "bus_clk", "ref_clk";
			power-domains = <0x38>;
			ranges;
			nvmem-cells = <0x26>;
			nvmem-cell-names = "soc_revision";
			clocks = <0x3 0x20 0x3 0x22>;

			dwc3@fe200000 {
				compatible = "snps,dwc3";
				status = "disabled";
				reg = <0x0 0xfe200000 0x0 0x40000>;
				interrupt-parent = <0x4>;
				interrupts = <0x0 0x41 0x4 0x0 0x45 0x4>;
				#stream-id-cells = <0x1>;
				iommus = <0xe 0x860>;
				snps,quirk-frame-length-adjustment = <0x20>;
				snps,refclk_fladj;
				snps,enable_guctl1_resume_quirk;
				snps,enable_guctl1_ipd_quirk;
				snps,xhci-stream-quirk;
			};
		};

		usb1@ff9e0000 {
			#address-cells = <0x2>;
			#size-cells = <0x2>;
			status = "disabled";
			compatible = "xlnx,zynqmp-dwc3";
			reg = <0x0 0xff9e0000 0x0 0x100>;
			clock-names = "bus_clk", "ref_clk";
			power-domains = <0x39>;
			ranges;
			nvmem-cells = <0x26>;
			nvmem-cell-names = "soc_revision";
			clocks = <0x3 0x21 0x3 0x22>;

			dwc3@fe300000 {
				compatible = "snps,dwc3";
				status = "disabled";
				reg = <0x0 0xfe300000 0x0 0x40000>;
				interrupt-parent = <0x4>;
				interrupts = <0x0 0x46 0x4 0x0 0x4a 0x4>;
				#stream-id-cells = <0x1>;
				iommus = <0xe 0x861>;
				snps,quirk-frame-length-adjustment = <0x20>;
				snps,refclk_fladj;
				snps,enable_guctl1_resume_quirk;
				snps,enable_guctl1_ipd_quirk;
				snps,xhci-stream-quirk;
			};
		};

		watchdog@fd4d0000 {
			compatible = "cdns,wdt-r1p2";
			status = "okay";
			interrupt-parent = <0x4>;
			interrupts = <0x0 0x71 0x1>;
			reg = <0x0 0xfd4d0000 0x0 0x1000>;
			timeout-sec = <0x1e>;
			clocks = <0x3 0x4b>;
			reset-on-timeout;
		};

		ams@ffa50000 {
			compatible = "xlnx,zynqmp-ams";
			status = "okay";
			interrupt-parent = <0x4>;
			interrupts = <0x0 0x38 0x4>;
			interrupt-names = "ams-irq";
			reg = <0x0 0xffa50000 0x0 0x800>;
			reg-names = "ams-base";
			#address-cells = <0x2>;
			#size-cells = <0x2>;
			#io-channel-cells = <0x1>;
			ranges;
			clocks = <0x3 0x46>;

			ams_ps@ffa50800 {
				compatible = "xlnx,zynqmp-ams-ps";
				status = "okay";
				reg = <0x0 0xffa50800 0x0 0x400>;
			};

			ams_pl@ffa50c00 {
				compatible = "xlnx,zynqmp-ams-pl";
				status = "okay";
				reg = <0x0 0xffa50c00 0x0 0x400>;
			};
		};

		dp@fd4a0000 {
			compatible = "xlnx,v-dp";
			status = "disabled";
			reg = <0x0 0xfd4a0000 0x0 0x1000>;
			interrupts = <0x0 0x77 0x4>;
			interrupt-parent = <0x4>;
			clock-names = "aclk", "aud_clk";
			power-domains = <0x3a>;
			xlnx,dp-version = "v1.2";
			xlnx,max-lanes = <0x2>;
			xlnx,max-link-rate = <0x83d60>;
			xlnx,max-bpc = <0x10>;
			xlnx,enable-ycrcb;
			xlnx,colormetry = "rgb";
			xlnx,bpc = <0x8>;
			xlnx,audio-chan = <0x2>;
			xlnx,dp-sub = <0xb>;
			xlnx,max-pclock-frequency = <0x493e0>;
			clocks = <0x3b 0x3 0x11>;
			linux,phandle = <0xa>;
			phandle = <0xa>;
		};

		dp_sub@fd4aa000 {
			compatible = "xlnx,dp-sub";
			status = "disabled";
			reg = <0x0 0xfd4aa000 0x0 0x1000 0x0 0xfd4ab000 0x0 0x1000 0x0 0xfd4ac000 0x0 0x1000>;
			reg-names = "blend", "av_buf", "aud";
			xlnx,output-fmt = "rgb";
			xlnx,vid-fmt = "yuyv";
			xlnx,gfx-fmt = "rgb565";
			power-domains = <0x3a>;
			linux,phandle = <0xb>;
			phandle = <0xb>;
		};

		dma@fd4c0000 {
			compatible = "xlnx,dpdma";
			status = "disabled";
			reg = <0x0 0xfd4c0000 0x0 0x1000>;
			interrupts = <0x0 0x7a 0x4>;
			interrupt-parent = <0x4>;
			clock-names = "axi_clk";
			power-domains = <0x3a>;
			dma-channels = <0x6>;
			#dma-cells = <0x1>;
			clocks = <0x3 0x14>;
			linux,phandle = <0x9>;
			phandle = <0x9>;

			dma-video0channel {
				compatible = "xlnx,video0";
			};

			dma-video1channel {
				compatible = "xlnx,video1";
			};

			dma-video2channel {
				compatible = "xlnx,video2";
			};

			dma-graphicschannel {
				compatible = "xlnx,graphics";
			};

			dma-audio0channel {
				compatible = "xlnx,audio0";
			};

			dma-audio1channel {
				compatible = "xlnx,audio1";
			};
		};

		i2c@80001000 {
			compatible = "xlnx,xps-iic-2.00.a";
			status = "disabled";
			clocks = <0x3 0x47>;
			interrupt-parent = <0x4>;
			interrupts = <0x0 0x59 0x4>;
			reg = <0x0 0x80001000 0x0 0x1000>;
		};

		i2c@80002000 {
			compatible = "xlnx,xps-iic-2.00.a";
			status = "disabled";
			clocks = <0x3 0x47>;
			interrupt-parent = <0x4>;
			interrupts = <0x0 0x5a 0x4>;
			reg = <0x0 0x80002000 0x0 0x1000>;
		};

		i2c@80003000 {
			compatible = "xlnx,xps-iic-2.00.a";
			status = "disabled";
			clocks = <0x3 0x47>;
			interrupt-parent = <0x4>;
			interrupts = <0x0 0x5b 0x4>;
			reg = <0x0 0x80003000 0x0 0x1000>;
		};

		i2c@80004000 {
			compatible = "xlnx,xps-iic-2.00.a";
			status = "disabled";
			clocks = <0x3 0x47>;
			interrupt-parent = <0x4>;
			interrupts = <0x0 0x5c 0x4>;
			reg = <0x0 0x80004000 0x0 0x1000>;
		};

		i2c@80005000 {
			compatible = "xlnx,xps-iic-2.00.a";
			status = "disabled";
			clocks = <0x3 0x47>;
			interrupt-parent = <0x4>;
			interrupts = <0x0 0x5d 0x4>;
			reg = <0x0 0x80005000 0x0 0x1000>;
		};

		i2c@80006000 {
			compatible = "xlnx,xps-iic-2.00.a";
			status = "disabled";
			clocks = <0x3 0x47>;
			interrupt-parent = <0x4>;
			interrupts = <0x0 0x5e 0x4>;
			reg = <0x0 0x80006000 0x0 0x1000>;
		};

		i2c@8000b000 {
			compatible = "xlnx,xps-iic-2.00.a";
			status = "disabled";
			clocks = <0x3 0x47>;
			interrupt-parent = <0x4>;
			interrupts = <0x0 0x6d 0x4>;
			reg = <0x0 0x8000b000 0x0 0x1000>;
		};

		spi@80010000 {
			compatible = "xlnx,xps-spi-2.00.a";
			status = "disabled";
			clock-names = "axi_clk", "axi4_clk", "spi_clk";
			clocks = <0x3 0x47 0x3 0x47 0x3 0x47>;
			interrupt-parent = <0x4>;
			interrupts = <0x0 0x5f 0x1>;
			reg = <0x0 0x80010000 0x0 0x10000>;
			num-cs = <0x1>;
			fifo-size = <0x10>;
			bits-per-word = <0x8>;
			#address-cells = <0x1>;
			#size-cells = <0x0>;

			spidev@0 {
				compatible = "spidev";
				reg = <0x0>;
				spi-max-frequency = <0x7735940>;
			};
		};

		spi@80020000 {
			compatible = "xlnx,xps-spi-2.00.a";
			status = "disabled";
			clock-names = "axi_clk", "axi4_clk", "spi_clk";
			clocks = <0x3 0x47 0x3 0x47 0x3 0x47>;
			interrupt-parent = <0x4>;
			interrupts = <0x0 0x60 0x1>;
			reg = <0x0 0x80020000 0x0 0x10000>;
			num-cs = <0x1>;
			fifo-size = <0x10>;
			bits-per-word = <0x8>;
			#address-cells = <0x1>;
			#size-cells = <0x0>;

			spidev@1 {
				compatible = "spidev";
				reg = <0x0>;
				spi-max-frequency = <0x7735940>;
			};
		};

		spi@80030000 {
			compatible = "xlnx,xps-spi-2.00.a";
			status = "disabled";
			clock-names = "axi_clk", "axi4_clk", "spi_clk";
			clocks = <0x3 0x47 0x3 0x47 0x3 0x47>;
			interrupt-parent = <0x4>;
			interrupts = <0x0 0x68 0x1>;
			reg = <0x0 0x80030000 0x0 0x10000>;
			num-cs = <0x1>;
			fifo-size = <0x10>;
			bits-per-word = <0x8>;
			#address-cells = <0x1>;
			#size-cells = <0x0>;

			spidev@2 {
				compatible = "spidev";
				reg = <0x0>;
				spi-max-frequency = <0x7735940>;
			};
		};
	};

	fclk0 {
		status = "disabled";
		compatible = "xlnx,fclk";
		clocks = <0x3 0x47>;
	};

	fclk1 {
		status = "disabled";
		compatible = "xlnx,fclk";
		clocks = <0x3 0x48>;
	};

	fclk2 {
		status = "disabled";
		compatible = "xlnx,fclk";
		clocks = <0x3 0x49>;
	};

	fclk3 {
		status = "disabled";
		compatible = "xlnx,fclk";
		clocks = <0x3 0x4a>;
	};

	pss_ref_clk {
		u-boot,dm-pre-reloc;
		compatible = "fixed-clock";
		#clock-cells = <0x0>;
		clock-frequency = <0x2faf080>;
		linux,phandle = <0x3c>;
		phandle = <0x3c>;
	};

	video_clk {
		u-boot,dm-pre-reloc;
		compatible = "fixed-clock";
		#clock-cells = <0x0>;
		clock-frequency = <0x19bfcc0>;
		linux,phandle = <0x3d>;
		phandle = <0x3d>;
	};

	pss_alt_ref_clk {
		u-boot,dm-pre-reloc;
		compatible = "fixed-clock";
		#clock-cells = <0x0>;
		clock-frequency = <0x0>;
		linux,phandle = <0x3e>;
		phandle = <0x3e>;
	};

	gt_crx_ref_clk {
		u-boot,dm-pre-reloc;
		compatible = "fixed-clock";
		#clock-cells = <0x0>;
		clock-frequency = <0x66ff300>;
		linux,phandle = <0x40>;
		phandle = <0x40>;
	};

	aux_ref_clk {
		u-boot,dm-pre-reloc;
		compatible = "fixed-clock";
		#clock-cells = <0x0>;
		clock-frequency = <0x19bfcc0>;
		linux,phandle = <0x3f>;
		phandle = <0x3f>;
	};

	clkc {
		u-boot,dm-pre-reloc;
		#clock-cells = <0x1>;
		compatible = "xlnx,zynqmp-clkc";
		clocks = <0x3c 0x3d 0x3e 0x3f 0x40>;
		clock-names = "pss_ref_clk", "video_clk", "pss_alt_ref_clk", "aux_ref_clk", "gt_crx_ref_clk";
		clock-output-names = "iopll", "rpll", "apll", "dpll", "vpll", "iopll_to_fpd", "rpll_to_fpd", "apll_to_lpd", "dpll_to_lpd", "vpll_to_lpd", "acpu", "acpu_half", "dbf_fpd", "dbf_lpd", "dbg_trace", "dbg_tstmp", "dp_video_ref", "dp_audio_ref", "dp_stc_ref", "gdma_ref", "dpdma_ref", "ddr_ref", "sata_ref", "pcie_ref", "gpu_ref", "gpu_pp0_ref", "gpu_pp1_ref", "topsw_main", "topsw_lsbus", "gtgref0_ref", "lpd_switch", "lpd_lsbus", "usb0_bus_ref", "usb1_bus_ref", "usb3_dual_ref", "usb0", "usb1", "cpu_r5", "cpu_r5_core", "csu_spb", "csu_pll", "pcap", "iou_switch", "gem_tsu_ref", "gem_tsu", "gem0_ref", "gem1_ref", "gem2_ref", "gem3_ref", "gem0_tx", "gem1_tx", "gem2_tx", "gem3_tx", "qspi_ref", "sdio0_ref", "sdio1_ref", "uart0_ref", "uart1_ref", "spi0_ref", "spi1_ref", "nand_ref", "i2c0_ref", "i2c1_ref", "can0_ref", "can1_ref", "can0", "can1", "dll_ref", "adma_ref", "timestamp_ref", "ams_ref", "pl0", "pl1", "pl2", "pl3", "wdt";
		linux,phandle = <0x3>;
		phandle = <0x3>;
	};

	dp_aclk {
		compatible = "fixed-clock";
		#clock-cells = <0x0>;
		clock-frequency = <0x5f5e100>;
		clock-accuracy = <0x64>;
		linux,phandle = <0x3b>;
		phandle = <0x3b>;
	};

	aliases {
		ethernet0 = "/amba/ethernet@ff0d0000";
		gpio0 = "/amba/gpio@ff0a0000";
		i2c1 = "/amba/i2c@ff030000";
		i2c0 = "/amba/i2c@ff020000";
		mmc0 = "/amba/sdhci@ff160000";
		mmc1 = "/amba/sdhci@ff170000";
		serial0 = "/amba/serial@ff010000";
		serial1 = "/amba/serial@ff000000";
		nand = "/amba/nand@ff100000";
	};

	chosen {
		linux,initrd-end = <0x0 0x3dec11b4>;
		linux,initrd-start = <0x0 0x3d1c6000>;
		bootargs = "earlycon clk_ignore_unused mem=496M console=ttyPS0,115200 ramdisk_size=33554432 root=/dev/ram rw earlyprintk";
		stdout-path = "serial0:115200n8";
	};

	memory@0 {
		device_type = "memory";
		reg = <0x0 0x0 0x0 0x40000000 0x0 0x0 0x0 0x0>;
	};

	reserved-memory {
		#address-cells = <0x2>;
		#size-cells = <0x2>;
		ranges;

		fpga0@800000000 {
			reg = <0x8 0x0 0x1 0x80000000>;
			no-map;
		};
	};
};
